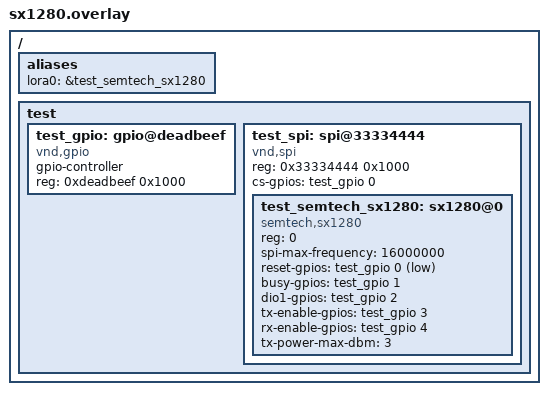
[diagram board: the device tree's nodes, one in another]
/*
 * Copyright (c) 2026 Giuseppe Fabiano <gfabiano40@gmail.com>
 * SPDX-License-Identifier: Apache-2.0
 */

/ {
	aliases {
		lora0 = &test_semtech_sx1280;
	};

	test {
		#address-cells = <1>;
		#size-cells = <1>;

		test_gpio: gpio@deadbeef {
			compatible = "vnd,gpio";
			gpio-controller;
			reg = <0xdeadbeef 0x1000>;
			#gpio-cells = <0x2>;
			status = "okay";
		};

		test_spi: spi@33334444 {
			#address-cells = <1>;
			#size-cells = <0>;
			compatible = "vnd,spi";
			reg = <0x33334444 0x1000>;
			status = "okay";

			cs-gpios = <&test_gpio 0 0>;

			test_semtech_sx1280: sx1280@0 {
				compatible = "semtech,sx1280";
				status = "okay";
				reg = <0>;
				spi-max-frequency = <16000000>;
				reset-gpios = <&test_gpio 0 GPIO_ACTIVE_LOW>;
				busy-gpios = <&test_gpio 1 GPIO_ACTIVE_HIGH>;
				dio1-gpios = <&test_gpio 2 GPIO_ACTIVE_HIGH>;
				tx-enable-gpios = <&test_gpio 3 GPIO_ACTIVE_HIGH>;
				rx-enable-gpios = <&test_gpio 4 GPIO_ACTIVE_HIGH>;
				tx-power-max-dbm = <3>;
			};
		};
	};
};
